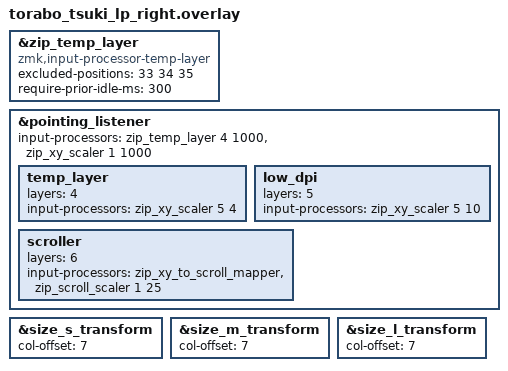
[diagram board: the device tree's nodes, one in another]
#include "torabo_tsuki_lp.dtsi"
#include <input/processors.dtsi>
#include <dt-bindings/zmk/input_transform.h>


&zip_temp_layer {
    compatible = "zmk,input-processor-temp-layer";
    excluded-positions = <
        33 34 35
    >;
    require-prior-idle-ms = <300>;
};

&pointing_listener {
    // input-processors = <&zip_xy_transform (INPUT_TRANSFORM_X_INVERT | INPUT_TRANSFORM_Y_INVERT)>;
    input-processors = <
        &zip_temp_layer 4 1000
        &zip_xy_scaler 1 1000
    >;

    temp_layer {
        layers = <4>;
        input-processors = <
            &zip_xy_scaler 5 4
        >;
    };

    low_dpi {
        layers = <5>;
        input-processors = <
            &zip_xy_scaler 5 10
        >;
    };

    scroller {
        layers = <6>;
        input-processors = <
            &zip_xy_to_scroll_mapper
            &zip_scroll_scaler 1 25

        >;
    };
};

&size_s_transform {
    col-offset = <7>;
};

&size_m_transform {
    col-offset = <7>;
};

&size_l_transform {
    col-offset = <7>;
};
